AUTOSAR XML (schema 4-2-2)
package /Components
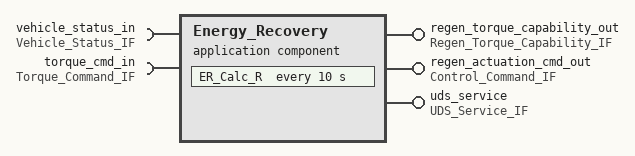
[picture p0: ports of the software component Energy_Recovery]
  application sw component type Energy_Recovery
    provide port regen_torque_capability_out: provided-interface=Regen_Torque_Capability_IF
    provide port regen_actuation_cmd_out: provided-interface=Control_Command_IF
    provide port uds_service: provided-interface=UDS_Service_IF
    require port vehicle_status_in: required-interface=Vehicle_Status_IF
    require port torque_cmd_in: required-interface=Torque_Command_IF
    behavior Energy_Recovery_InternalBehavior
      data received event Regen_Command_Update: start-on-event=ER_Apply_R
      init event ER_Init: start-on-event=ER_Init_R
      operation invoked event Diag_ReadData_Invoked: start-on-event=ER_Diag_R
      timing event ER_Periodic_10ms: start-on-event=ER_Calc_R, period=10
      4 x runnable:
        ER_Init_R
          parameter access PA_Init_SOCLimit: accessed-parameter=regen_torque_capability_out.regen_torque_capability_nm
        ER_Calc_R: minimum-start-interval=10
          data-receive-point-by-arguments:
            access VA_Arg_BrakeStatus: accessed-variable=vehicle_status_in.brake_status
            access VA_Arg_VehicleSpeed: accessed-variable=vehicle_status_in.vehicle_speed_kph
          data-send-points:
            access VA_Send_RegenCapability: accessed-variable=regen_torque_capability_out.regen_torque_capability_nm
        ER_Apply_R
          data-receive-point-by-values:
            access VA_Val_RegenTorqueCmd: accessed-variable=torque_cmd_in.regen_torque_cmd_nm
          data-send-points:
            access VA_Send_RegenActuationCmd: accessed-variable=regen_actuation_cmd_out.regen_actuation_cmd_out
        ER_Diag_R
